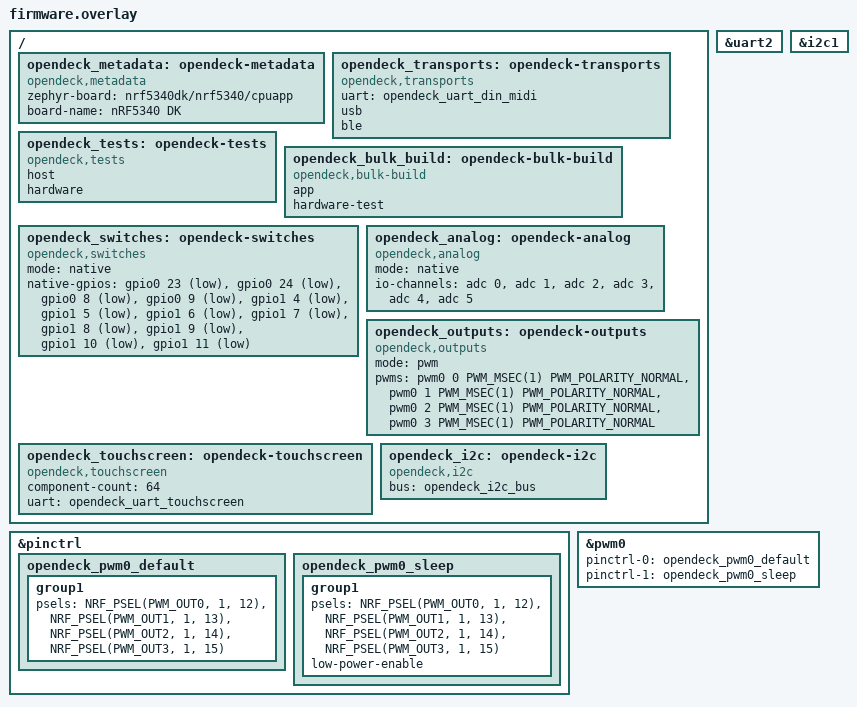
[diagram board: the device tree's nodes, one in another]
/ {
    opendeck_metadata: opendeck-metadata {
        compatible = "opendeck,metadata";
        zephyr-board = "nrf5340dk/nrf5340/cpuapp";
        board-name = "nRF5340 DK";
    };

    opendeck_transports: opendeck-transports {
        compatible = "opendeck,transports";
        uart = <&opendeck_uart_din_midi>;
        usb;
        ble;
    };

    opendeck_tests: opendeck-tests {
        compatible = "opendeck,tests";
        host;
        hardware;
    };

    opendeck_bulk_build: opendeck-bulk-build {
        compatible = "opendeck,bulk-build";
        app;
        hardware-test;
    };

    opendeck_switches: opendeck-switches {
        compatible = "opendeck,switches";
        mode = "native";
        native-gpios =
            <&gpio0 23 (GPIO_PULL_UP | GPIO_ACTIVE_LOW)>, /* Button 1 */
            <&gpio0 24 (GPIO_PULL_UP | GPIO_ACTIVE_LOW)>, /* Button 2 */
            <&gpio0 8 (GPIO_PULL_UP | GPIO_ACTIVE_LOW)>,  /* Button 3 */
            <&gpio0 9 (GPIO_PULL_UP | GPIO_ACTIVE_LOW)>,  /* Button 4 */
            <&gpio1 4 (GPIO_PULL_UP | GPIO_ACTIVE_LOW)>,  /* D2 */
            <&gpio1 5 (GPIO_PULL_UP | GPIO_ACTIVE_LOW)>,  /* D3 */
            <&gpio1 6 (GPIO_PULL_UP | GPIO_ACTIVE_LOW)>,  /* D4 */
            <&gpio1 7 (GPIO_PULL_UP | GPIO_ACTIVE_LOW)>,  /* D5 */
            <&gpio1 8 (GPIO_PULL_UP | GPIO_ACTIVE_LOW)>,  /* D6 */
            <&gpio1 9 (GPIO_PULL_UP | GPIO_ACTIVE_LOW)>,  /* D7 */
            <&gpio1 10 (GPIO_PULL_UP | GPIO_ACTIVE_LOW)>, /* D8 */
            <&gpio1 11 (GPIO_PULL_UP | GPIO_ACTIVE_LOW)>; /* D9 */
    };

    opendeck_analog: opendeck-analog {
        compatible = "opendeck,analog";
        mode = "native";
        io-channels =
            <&adc 0>, /* A0 / P0.04 / AIN0 */
            <&adc 1>, /* A1 / P0.05 / AIN1 */
            <&adc 2>, /* A2 / P0.06 / AIN2 */
            <&adc 3>, /* A3 / P0.07 / AIN3 */
            <&adc 4>, /* A4 / P0.25 / AIN4 */
            <&adc 5>; /* A5 / P0.26 / AIN5 */
    };

    opendeck_outputs: opendeck-outputs {
        compatible = "opendeck,outputs";
        mode = "pwm";
        pwms =
            <&pwm0 0 PWM_MSEC(1) PWM_POLARITY_NORMAL>,   /* D10 */
            <&pwm0 1 PWM_MSEC(1) PWM_POLARITY_NORMAL>,   /* D11 */
            <&pwm0 2 PWM_MSEC(1) PWM_POLARITY_NORMAL>,   /* D12 */
            <&pwm0 3 PWM_MSEC(1) PWM_POLARITY_NORMAL>;   /* D13 */
    };

    opendeck_touchscreen: opendeck-touchscreen {
        compatible = "opendeck,touchscreen";
        component-count = <64>;
        uart = <&opendeck_uart_touchscreen>;
    };
    opendeck_i2c: opendeck-i2c {
        compatible = "opendeck,i2c";
        bus = <&opendeck_i2c_bus>;
    };
};

&uart2 {
    status = "okay";
};

&i2c1 {
    status = "okay";
};

&pinctrl {
    opendeck_pwm0_default: opendeck_pwm0_default {
        group1 {
            psels = <NRF_PSEL(PWM_OUT0, 1, 12)>,
                    <NRF_PSEL(PWM_OUT1, 1, 13)>,
                    <NRF_PSEL(PWM_OUT2, 1, 14)>,
                    <NRF_PSEL(PWM_OUT3, 1, 15)>;
        };
    };

    opendeck_pwm0_sleep: opendeck_pwm0_sleep {
        group1 {
            psels = <NRF_PSEL(PWM_OUT0, 1, 12)>,
                    <NRF_PSEL(PWM_OUT1, 1, 13)>,
                    <NRF_PSEL(PWM_OUT2, 1, 14)>,
                    <NRF_PSEL(PWM_OUT3, 1, 15)>;
            low-power-enable;
        };
    };

};

&pwm0 {
    pinctrl-0 = <&opendeck_pwm0_default>;
    pinctrl-1 = <&opendeck_pwm0_sleep>;
    pinctrl-names = "default", "sleep";
    status = "okay";
};
